# MINI58DE_v1 register map
File version: 1.0
Registers are 32-bit, read-write, reset 0x0 unless marked. A register's access mark holds for its fields unless they carry their own. Offsets are from the block's base; [hi:lo] are bit positions; 'fields as' and 'values as' point back to an identical list.

## CLK — CLK Register Map
Base 0x50000200
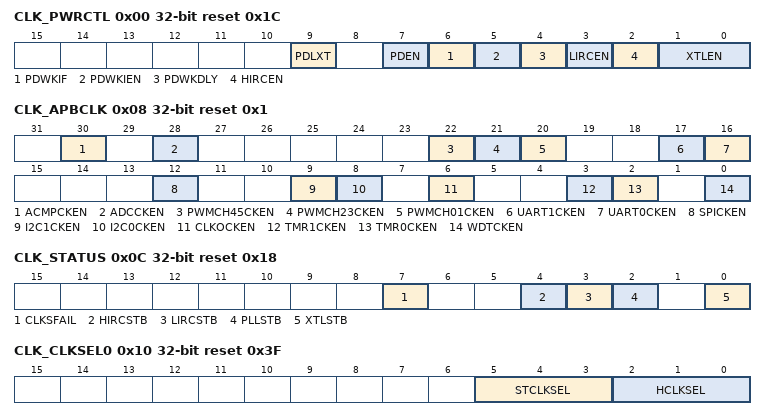
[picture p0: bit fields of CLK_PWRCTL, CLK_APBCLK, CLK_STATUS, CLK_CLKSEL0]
0x00 CLK_PWRCTL reset 0x1C — System Power-down Control Register
  [9] PDLXT — Enable LXT In Power-down Mode. This bit controls the crystal oscillator active or not in Power-down mode.
    0=No effect to Power-down mode; 1=If XTLEN[1:0] = 10, LXT is still active in Power-down mode
  [7] PDEN — System Power-down Enable Bit (Write Protect). When chip wakes up from Power-down mode, this bit is cleared by hardware. User needs to set this bit again for next Power-down. In Power-down mode, 4~24 MHz external high speed crystal oscillator (HXT), 32.768 kHz external low speed crystal oscillator (LXT), and the 22.1184 MHz internal high speed oscillator (HIRC) will be disabled in this mode, and 10 kHz internal low speed RC oscillator (LIRC) are not controlled by Power-down mode. In Power-down mode, the PLL and system clock are disabled, and ignored the clock source selection. The clocks of peripheral are not controlled by Power-down mode, if the peripheral clock source is from 10 kHz internal low speed oscillator.
    0=Chip operating normally or chip in Idle mode because of WFI command; 1=Chip enters Power-down mode instantly or waits CPU sleep command WFI
  [6] PDWKIF — Power-down Mode Wake-up Interrupt Status. Set by "Power-down wake-up event", which indicates that resume from Power-down mode" The flag is set if the GPIO, UART, WDT, ACMP, Timer or BOD wake-up occurred. Note: This bit works only if PDWKIEN (CLK_PWRCTL[5]) set to 1. Write 1 to clear the bit to 0.
  [5] PDWKIEN — Power-down Mode Wake-up Interrupt Enable Bit (Write Protect). Note: The interrupt will occur when both PDWKIF and PDWKIEN are high.
    0=Power-down mode wake-up interrupt Disabled; 1=Power-down mode wake-up interrupt Enabled
  [4] PDWKDLY — Wake-up Delay Counter Enable Bit (Write Protect). When the chip wakes up from Power-down mode, the clock control will delay certain clock cycles to wait system clock stable. The delayed clock cycle is 4096 clock cycles when chip work at 4~24 MHz external high speed crystal (HXT), 4096 clock cycles for 32.768 kHz external low speed crystal (LXT), and 16 clock cycles when chip works at 22.1184 MHz internal high speed RC oscillator (HIRC).
    0=Clock cycles delay Disabled; 1=Clock cycles delay Enabled
  [3] LIRCEN — LIRC Enable Bit (Write Protect)
    0=10 kHz internal low speed RC oscillator (LIRC) Disabled; 1=10 kHz internal low speed RC oscillator (LIRC) Enabled
  [2] HIRCEN — HIRC Enable Bit (Write Protect). Note: The default of HIRCEN bit is 1.
    0=22.1184 MHz internal high speed RC oscillator (HIRC) Disabled; 1=22.1184 MHz internal high speed RC oscillator (HIRC) Enabled
  [1:0] XTLEN — External HXT Or LXT Crystal Oscillator Enable Bit (Write Protect). The default clock source is from HIRC. These two bits are default set to "00" and the XT1_IN and XT1_OUT pins are GPIO. Note: To enable external XTAL function, ALT[1:0] and MFP[1:0] bits must also be set in SYS_P5_MFP.
    0=XT1_IN and XT1_OUT are GPIO, disable both LXT HXT (default); 1=HXT Enabled; 2=LXT Enabled; 3=XT1_IN is external clock input pin, XT1_OUT is GPIO
0x04 CLK_AHBCLK reset 0x5 — AHB Devices Clock Enable Control Register
  [2] ISPCKEN — Flash ISP Controller Clock Enable Bit
    0=Flash ISP peripheral clock Disabled; 1=Flash ISP peripheral clock Enabled
0x08 CLK_APBCLK reset 0x1 — APB Devices Clock Enable Control Register
  [30] ACMPCKEN — Analog Comparator Clock Enable Bit
    0=Analog Comparator clock Disabled; 1=Analog Comparator clock Enabled
  [28] ADCCKEN — Analog-digital-converter (ADC) Clock Enable Bit
    0=ADC peripheral clock Disabled; 1=ADC peripheral clock Enabled
  [22] PWMCH45CKEN — PWM_45 Clock Enable Bit
    0=PWM45 clock Disabled; 1=PWM45 clock Enabled
  [21] PWMCH23CKEN — PWM_23 Clock Enable Bit
    0=PWM23 clock Disabled; 1=PWM23 clock Enabled
  [20] PWMCH01CKEN — PWM_01 Clock Enable Bit
    0=PWM01 clock Disabled; 1=PWM01 clock Enabled
  [17] UART1CKEN — UART1 Clock Enable Bit
    0=UART1 clock Disabled; 1=UART1 clock Enabled
  [16] UART0CKEN — UART0 Clock Enable Bit
    0=UART0 clock Disabled; 1=UART0 clock Enabled
  [12] SPICKEN — SPI Clock Enable Bit
    0=SPI peripheral clock Disabled; 1=SPI peripheral clock Enabled
  [9] I2C1CKEN — I2C1 Clock Enable Bit
    0=I2C1 clock Disabled; 1=I2C1 clock Enabled
  [8] I2C0CKEN — I2C0 Clock Enable Bit
    0=I2C0 clock Disabled; 1=I2C0 clock Enabled
  [6] CLKOCKEN — Frequency Divider Output Clock Enable Bit
    0=CLKO clock Disabled; 1=CLKO clock Enabled
  [3] TMR1CKEN — Timer1 Clock Enable Bit
    0=Timer1 clock Disabled; 1=Timer1 clock Enabled
  [2] TMR0CKEN — Timer0 Clock Enable Bit
    0=Timer0 clock Disabled; 1=Timer0 clock Enabled
  [0] WDTCKEN — Watchdog Timer Clock Enable Bit (Write Protect). Note: This bit is the protected bit, and programming it needs to write 0x59, 0x16, and 0x88 to address 0x5000_0100 to disable register protection. Refer to the register SYS_REGLCTL at address SYS_BA + 0x100.
    0=Watchdog Timer clock Disabled; 1=Watchdog Timer clock Enabled
0x0C CLK_STATUS reset 0x18 — Clock Status Monitor Register
  [7] CLKSFAIL ro — Clock Switch Fail Flag (Read Only). This bit is updated when software switches system clock source. If switch target clock is stable, this bit will be set to 0. If switch target clock is not stable, this bit will be set to 1. Note: This bit is read only. After selected clock source is stable, hardware will switch system clock to selected clock automatically, and CLKSFAIL will be cleared automatically by hardware.
    0=Clock switching success; 1=Clock switching failure
  [4] HIRCSTB ro — HIRC Clock Source Stable Flag (Read Only)
    0=HIRC clock is not stable or disabled; 1=HIRC clock is stable and enabled
  [3] LIRCSTB ro — LIRC Clock Source Stable Flag (Read Only)
    0=LIRC clock is not stable or disabled; 1=LIRC clock is stable and enabled
  [2] PLLSTB ro — Internal PLL Clock Source Stable Flag (Read Only)
    0=Internal PLL clock is not stable or disabled; 1=Internal PLL clock is stable and enabled
  [0] XTLSTB — HXT Or LXT Clock Source Stable Flag
    0=HXT or LXT clock is not stable or disabled; 1=HXT or LXT clock is stable and enabled
0x10 CLK_CLKSEL0 reset 0x3F — Clock Source Select Control Register 0
  [5:3] STCLKSEL — Cortex-M0 SysTick Clock Source Selection (Write Protect). Note3: To set CLK_PWRCTL[1:0], select HXT or LXT crystal clock.
    0=Clock source is from HXT or LXT; 2=Clock source is from HXT/2 or LXT/2; 3=Clock source is from HCLK/2; 7=Clock source is from HIRC/2
  [2:0] HCLKSEL — HCLK Clock Source Selection (Write Protect). Note1: Before clock switching, the related clock sources (both pre-select and new-select) must be turn-on and stable. Note2: These bits are protected bit, and programming them needs to write 0x59, 0x16, and 0x88 to address 0x5000_0100 to disable register protection. Refer to the register SYS_REGLCTL at address SYS_BA + 0x100. Note3: To set CLK_PWRCTL[1:0] to select HXT or LXT crystal clock.
    0=Clock source is from HXT or LXT; 2=Clock source is from PLL; 3=Clock source is from LIRC; 7=Clock source is from HIRC
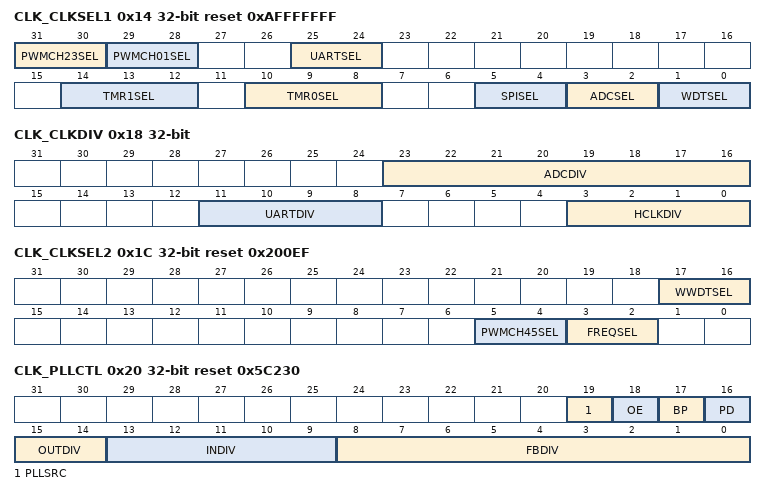
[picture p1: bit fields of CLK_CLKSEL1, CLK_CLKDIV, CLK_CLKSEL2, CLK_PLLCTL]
0x14 CLK_CLKSEL1 reset 0xAFFFFFFF — Clock Source Select Control Register 1
  [31:30] PWMCH23SEL — PWM2 And PWM3 Clock Source Selection. PWM2 and PWM3 use the same peripheral clock source; Both of them use the same prescaler.
    2=Clock source is from HCLK
  [29:28] PWMCH01SEL — PWM0 And PWM1 Clock Source Selection. PWM0 and PWM1 use the same peripheral clock source. Both of them use the same prescaler.
    2=Clock source is from HCLK
  [25:24] UARTSEL — UART Clock Source Selection. Note: To set CLK_PWRCTL[1:0], select HXT or LXT crystal clock.
    0=Clock source is from HXT or LXT; 1=Clock source is from PLL; 2=Clock source is from HIRC; 3=Clock source is from HIRC
  [14:12] TMR1SEL — TIMER1 Clock Source Selection. Note: To set CLK_PWRCTL[1:0], select HXT or LXT crystal clock.
    0=Clock source is from HXT or LXT; 1=Clock source is from LIRC; 2=Clock source is from HCLK; 3=Clock source is from external trigger; 7=Clock source is from HIRC
  [10:8] TMR0SEL — TIMER0 Clock Source Selection. Note: To set CLK_PWRCTL[1:0], select HXT or LXT crystal clock.
    values as TMR1SEL
  [5:4] SPISEL — SPI Clock Source Selection. Note: To set CLK_PWRCTL[1:0], select HXT or LXT crystal clock.
    0=Clock source is from HXT or LXT; 1=Clock source is from HCLK; 2=Clock source is from PLL
  [3:2] ADCSEL — ADC Peripheral Clock Source Selection. Note: To set CLK_PWRCTL[1:0], select HXT or LXT crystal clock.
    0=Clock source is from HXT or LXT; 1=Clock source is from PLL; 2=Clock source is from HCLK; 3=Clock source is from HIRC
  [1:0] WDTSEL — WDT CLK Clock Source Selection (Write Protect). Note1: These bits are the protected bit, and programming them needs to write 0x59, 0x16, and 0x88 to address 0x5000_0100 to disable register protection. Refer to the register SYS_REGLCTL at address SYS_BA + 0x100. Note2: To set CLK_PWRCTL[1:0], select HXT or LXT crystal clock.
    0=Clock source is from HXT or LXT; 2=Clock source is from HCLK/2048 clock; 3=Clock source is from LIRC
0x18 CLK_CLKDIV — Clock Divider Number Register
  [23:16] ADCDIV — ADC Peripheral Clock Divide Number From ADC Peripheral Clock Source
  [11:8] UARTDIV — UART Clock Divide Number From UART Clock Source
  [3:0] HCLKDIV — HCLK Clock Divide Number From HCLK Clock Source
0x1C CLK_CLKSEL2 reset 0x200EF — Clock Source Select Control Register 2
  [17:16] WWDTSEL — Window Watchdog Timer Clock Source Selection
    2=Clock source from HCLK/2048 clock; 3=Clock source from 10 kHz internal low speed RC oscillator (LIRC)
  [5:4] PWMCH45SEL — PWM4 And PWM5 Clock Source Selection. PWM4 and PWM5 use the same peripheral clock source; Both of them use the same prescaler.
    2=Clock source is from HCLK
  [3:2] FREQSEL — Clock Divider Clock Source Selection. Note: To set CLK_PWRCTL[1:0], select HXT or LXT crystal clock.
    0=Clock source is from HXT or LXT; 1=Clock source is from LIRC; 2=Clock source is from HCLK; 3=Clock source is from HIRC
0x20 CLK_PLLCTL reset 0x5C230 — PLL Control Register
  [19] PLLSRC — PLL Source Clock Selection
    0=PLL source clock from HXT; 1=PLL source clock from HIRC
  [18] OE — PLL OE (FOUT Enable) Pin Control
    0=PLL FOUT Enabled; 1=PLL FOUT is fixed low
  [17] BP — PLL Bypass Control
    0=PLL is in Normal mode (default); 1=PLL clock output is same as PLL source clock input
  [16] PD — Power-down Mode. If the PDEN bit is set to 1 in CLK_PWRCTL register, the PLL will enter Power-down mode too.
    0=PLL is in Normal mode; 1=PLL is in Power-down mode (default)
  [15:14] OUTDIV — PLL Output Divider Control. Refer to the formulas below the table.
  [13:9] INDIV — PLL Input Divider Control. Refer to the formulas below the table.
  [8:0] FBDIV — PLL Feedback Divider Control. Refer to the formulas below the table.
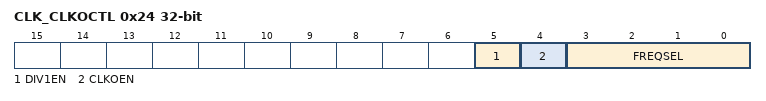
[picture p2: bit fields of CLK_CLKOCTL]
0x24 CLK_CLKOCTL — Frequency Divider Control Register
  [5] DIV1EN — Frequency Divider One Enable Bit
    0=Divider output frequency is depended on FREQSEL value; 1=Divider output frequency is the same as input clock frequency
  [4] CLKOEN — Frequency Divider Enable Bit
    0=Frequency Divider Disabled; 1=Frequency Divider Enabled
  [3:0] FREQSEL — Divider Output Frequency Selection. The formula of output frequency is. Fin is the input clock frequency. Fout is the frequency of divider output clock. N is the 4-bit value of FREQSEL(CLK_CLKOCTL[3:0]).
